# ipro7 register map
Vendor: intelpro; Series: BTBLE
CPU: ipro7, little endian
Registers are 32-bit, read-write, reset 0x0 unless marked. A register's access mark holds for its fields unless they carry their own. Offsets are from the block's base; [hi:lo] are bit positions.

## EF
Base 0x30008000
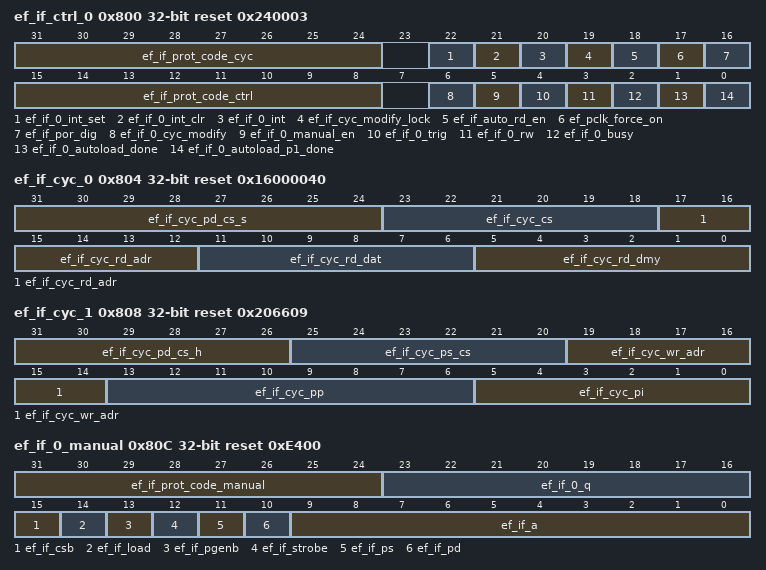
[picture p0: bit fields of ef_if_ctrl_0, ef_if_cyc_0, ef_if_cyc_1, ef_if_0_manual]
0x800 ef_if_ctrl_0 reset 0x240003 (reset mask 0xFFEFFFF8)
  [31:24] ef_if_prot_code_cyc — enter 8'hbf to unlock ef_if_cyc
  [22] ef_if_0_int_set — 1:set interrupt
  [21] ef_if_0_int_clr — 1:clear interrupt
  [20] ef_if_0_int ro — interrupt status
  [19] ef_if_cyc_modify_lock — write lock of ef_if_cyc_modify
  [18] ef_if_auto_rd_en — 1:auto update data register when efuse programed done
  [17] ef_pclk_force_on — 1:force p_aslice pclk always on
  [16] ef_if_por_dig — 0:read efuse 1:pull por33 and vddq to write efuse
  [15:8] ef_if_prot_code_ctrl — enter 8'hbf to unlock ef_if_trig
  [6] ef_if_0_cyc_modify — 0:default cycle parameter 1:manual cycle parameter
  [5] ef_if_0_manual_en — 0:auto mode 1:manual mode
  [4] ef_if_0_trig — 1:trigger ef_ctrl_if FSM
  [3] ef_if_0_rw — 0:read 1:write
  [2] ef_if_0_busy ro — 0:idle 1:busy
  [1] ef_if_0_autoload_done ro — 0:autoload running 1:autoload finish
  [0] ef_if_0_autoload_p1_done ro — 0:autoload phase1 running 1:autoload phase1 finish
0x804 ef_if_cyc_0 reset 0x16000040
  [31:24] ef_if_cyc_pd_cs_s, [23:18] ef_if_cyc_cs, [17:12] ef_if_cyc_rd_adr, [11:6] ef_if_cyc_rd_dat, [5:0] ef_if_cyc_rd_dmy
0x808 ef_if_cyc_1 reset 0x206609
  [31:26] ef_if_cyc_pd_cs_h, [25:20] ef_if_cyc_ps_cs, [19:14] ef_if_cyc_wr_adr, [13:6] ef_if_cyc_pp, [5:0] ef_if_cyc_pi
0x80C ef_if_0_manual reset 0xE400 (reset mask 0xFF00FFFF)
  [31:24] ef_if_prot_code_manual — enter 8'hbf to unlock ef_if_manual
  [23:16] ef_if_0_q ro
  [15] ef_if_csb
  [14] ef_if_load
  [13] ef_if_pgenb
  [12] ef_if_strobe
  [11] ef_if_ps
  [10] ef_if_pd
  [9:0] ef_if_a
0x810 ef_if_0_status reset 0xE400 (reset mask 0x0)
  [31:0] ef_if_0_status ro
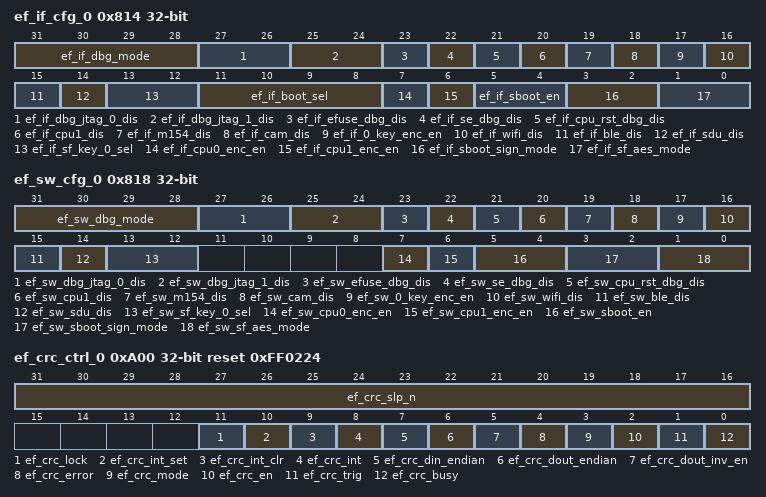
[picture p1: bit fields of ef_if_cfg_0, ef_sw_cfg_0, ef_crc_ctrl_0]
0x814 ef_if_cfg_0 reset not defined
  [31:28] ef_if_dbg_mode ro — 4'b0000:open mode 4'b0001:password mode 4'b0010:password mode 4'b0011:password mode others:close mode
  [27:26] ef_if_dbg_jtag_0_dis ro — 2'b00:enable JTAG port 0 others:disable JTAG port 0
  [25:24] ef_if_dbg_jtag_1_dis ro — 2'b00:enable JTAG port 1 others:disable JTAG port 1
  [23] ef_if_efuse_dbg_dis ro — 2'b00:enable eFuse manual mode others:disable eFuse manual mode
  [22] ef_if_se_dbg_dis ro — 2'b00:unprotected Others:disable secure engine debug mode
  [21] ef_if_cpu_rst_dbg_dis ro — 2'b00:unprotected Others:disable cpu reset debug mode
  [20] ef_if_cpu1_dis ro — 1:disable cpu1
  [19] ef_if_m154_dis ro — 1:disable m154
  [18] ef_if_cam_dis ro — 1:disable camera
  [17] ef_if_0_key_enc_en ro — 2'b00:disable efuse 0 key slot and debug port password encryption Others:enable efuse 0 key slot and debug port password encryption
  [16] ef_if_wifi_dis ro — 1:disable wifi
  [15] ef_if_ble_dis ro — 1:disable ble
  [14] ef_if_sdu_dis ro — 1:disable sdu
  [13:12] ef_if_sf_key_0_sel ro — 2'b00:select key slot 2 2'b01:select key slot 3 2'b10:select key slot 4 2'b11:select key slot 2
  [11:8] ef_if_boot_sel ro — [3] 1:APP on E21 [2] 1:APP on M0 [1] 1:boot from E21 [0] 1:boot from M0
  [7] ef_if_cpu0_enc_en ro — 1:encrypt cpu0
  [6] ef_if_cpu1_enc_en ro — 1:encrypt cpu1
  [5:4] ef_if_sboot_en ro — 4'b0000:secure boot disable others:secure boot enable
  [3:2] ef_if_sboot_sign_mode ro — 2'b00:unsign 2'b01:sign CPU 0 only 2'b10:sign CPU 1 only 2'b11:sign CPU 0 and CPU 1
  [1:0] ef_if_sf_aes_mode ro — 2'b00:plaintext 2'b01:AES-128 2'b10:AES-192 2'b11:AES-256
0x818 ef_sw_cfg_0
  [31:28] ef_sw_dbg_mode — 4'b0000:open mode 4'b0001:password mode 4'b0010:password mode 4'b0011:password mode others:close mode
  [27:26] ef_sw_dbg_jtag_0_dis — 2'b00:enable JTAG port 0 others:disable JTAG port 0
  [25:24] ef_sw_dbg_jtag_1_dis — 2'b00:enable JTAG port 1 others:disable JTAG port 1
  [23] ef_sw_efuse_dbg_dis — 2'b00:enable eFuse manual mode others:disable eFuse manual mode
  [22] ef_sw_se_dbg_dis — 2'b00:unprotected Others:disable secure engine debug mode
  [21] ef_sw_cpu_rst_dbg_dis — 2'b00:unprotected Others:disable cpu reset debug mode
  [20] ef_sw_cpu1_dis — 1:disable cpu1
  [19] ef_sw_m154_dis — 1:disable m154
  [18] ef_sw_cam_dis — 1:disable camera
  [17] ef_sw_0_key_enc_en — 2'b00:disable efuse 0 key slot and debug port password encryption Others:enable efuse 0 key slot and debug port password encryption
  [16] ef_sw_wifi_dis — 1:disable wifi
  [15] ef_sw_ble_dis — 1:disable ble
  [14] ef_sw_sdu_dis — 1:disable sdu
  [13:12] ef_sw_sf_key_0_sel — 2'b00:select key slot 2 2'b01:select key slot 3 2'b10:select key slot 4 2'b11:select key slot 2
  [7] ef_sw_cpu0_enc_en — 1:encrypt cpu0
  [6] ef_sw_cpu1_enc_en — 1:encrypt cpu1
  [5:4] ef_sw_sboot_en — 4'b0000:secure boot disable others:secure boot enable
  [3:2] ef_sw_sboot_sign_mode — 2'b00:unsign 2'b01:sign CPU 0 only 2'b10:sign CPU 1 only 2'b11:sign CPU 0 and CPU 1
  [1:0] ef_sw_sf_aes_mode — 2'b00:plaintext 2'b01:AES-128 2'b10:AES-192 2'b11:AES-256
0x81C ef_reserved reset 0xFFFF
0x820 ef_if_ana_trim_0 reset not defined
  [31:0] ef_if_ana_trim_0 ro
0x824 ef_if_sw_usage_0 reset not defined
  [31:0] ef_if_sw_usage_0 ro
0x828 ef_if_0_manual_1
  [2:0] ef_if_xtal_type — setup xtal for program mode 0:rc32m, 1:24m, 2:32m, 3:38.4m, 4:40m, 5:26m, 6:rc32m, 7:rc32m
0xA00 ef_crc_ctrl_0 reset 0xFF0224 (reset mask 0xFFFFFEEE)
  [31:16] ef_crc_slp_n — sleep number of words
  [11] ef_crc_lock
  [10] ef_crc_int_set — 1:set interrupt
  [9] ef_crc_int_clr — 1:clear interrupt
  [8] ef_crc_int ro — interrupt value
  [7] ef_crc_din_endian — 0:little-endian 1:big-endian
  [6] ef_crc_dout_endian — 0:little-endian 1:big-endian
  [5] ef_crc_dout_inv_en — 1:CRC data output invert enable
  [4] ef_crc_error ro — 1:CRC error
  [3] ef_crc_mode — 0:single mode 1:loop mode
  [2] ef_crc_en — 1:enable CRC engine
  [1] ef_crc_trig — 1:trigger CRC FSM
  [0] ef_crc_busy ro — 0:idle 1:busy
0xA04 ef_crc_ctrl_1 reset 0xFFFFFFFF
  [31:0] ef_crc_data_0_en — enable crc check for ef_data_0 [0] 0x00 [1] 0x04 … [31] 0x7C
0xA08 ef_crc_ctrl_2 reset 0xFFFFFFFF
  [31:0] ef_crc_data_1_en — enable crc check for ef_data_1 [0] 0x80 [1] 0x84 … [31] 0xFC
0xA0C ef_crc_ctrl_3 reset 0xFFFFFFFF
  [31:0] ef_crc_iv — CRC initial value
0xA10 ef_crc_ctrl_4 reset 0xC2A8FA9D
  [31:0] ef_crc_golden — CRC golden value
0xA14 ef_crc_ctrl_5 reset 0xFFFFFFFF (reset mask 0x0)
  [31:0] ef_crc_dout ro — CRC digest used for test mdoe only
